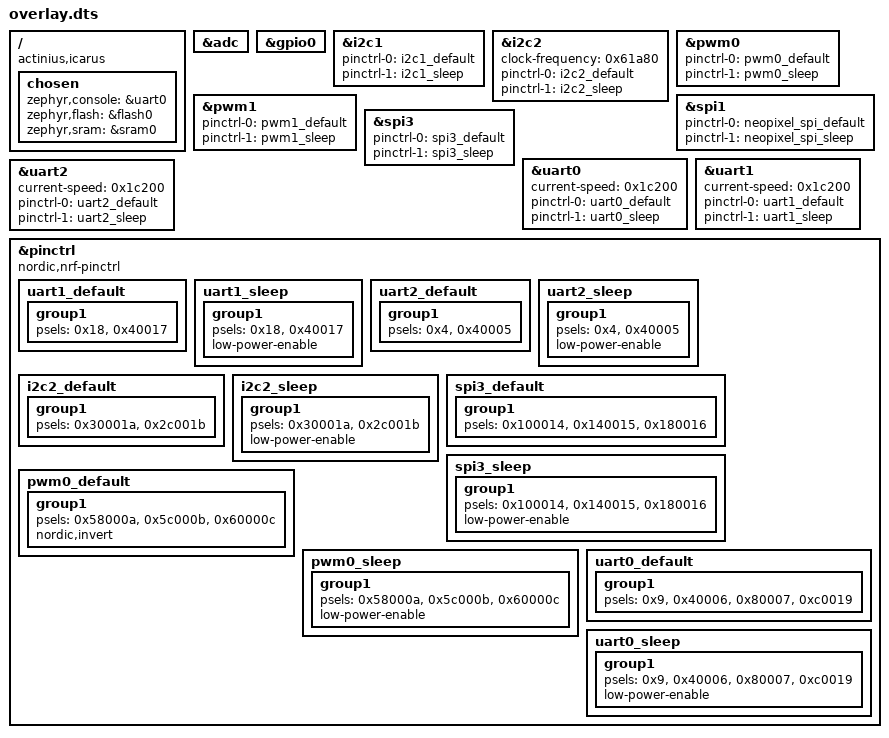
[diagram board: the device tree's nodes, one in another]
/ {
	compatible = "actinius,icarus";
	chosen {
		zephyr,console = &uart0;
		zephyr,flash = &flash0;
		zephyr,sram = &sram0;
	};
};
&adc{
	status = "okay";
};
&gpio0{
	status = "okay";
};
&i2c1{
	status = "okay";
	pinctrl-0 = < &i2c1_default >;
	pinctrl-1 = < &i2c1_sleep >;
	pinctrl-names = "default", "sleep";
};
&i2c2{
	clock-frequency = < 0x61a80 >;
	status = "okay";
	pinctrl-0 = < &i2c2_default >;
	pinctrl-1 = < &i2c2_sleep >;
	pinctrl-names = "default", "sleep";
};
&pwm0{
	status = "okay";
	pinctrl-0 = < &pwm0_default >;
	pinctrl-1 = < &pwm0_sleep >;
	pinctrl-names = "default", "sleep";
};
&pwm1{
	status = "okay";
	pinctrl-0 = < &pwm1_default >;
	pinctrl-1 = < &pwm1_sleep >;
	pinctrl-names = "default", "sleep";
};
&spi1{
	status = "okay";
	pinctrl-0 = < &neopixel_spi_default >;
	pinctrl-1 = < &neopixel_spi_sleep >;
	pinctrl-names = "default", "sleep";
};
&spi3{
	status = "okay";
	pinctrl-0 = < &spi3_default >;
	pinctrl-1 = < &spi3_sleep >;
	pinctrl-names = "default", "sleep";
};
&uart0{
	status = "okay";
	current-speed = < 0x1c200 >;
	pinctrl-0 = < &uart0_default >;
	pinctrl-1 = < &uart0_sleep >;
	pinctrl-names = "default", "sleep";
};
&uart1{
	status = "okay";
	current-speed = < 0x1c200 >;
	pinctrl-0 = < &uart1_default >;
	pinctrl-1 = < &uart1_sleep >;
	pinctrl-names = "default", "sleep";
};
&uart2{
	current-speed = < 0x1c200 >;
	pinctrl-0 = < &uart2_default >;
	pinctrl-1 = < &uart2_sleep >;
	pinctrl-names = "default", "sleep";
};
&pinctrl{
	compatible = "nordic,nrf-pinctrl";
	uart1_default: uart1_default {
		group1 {
			psels = < 0x18 >, < 0x40017 >;
		};
	};
	uart1_sleep: uart1_sleep {
		group1 {
			psels = < 0x18 >, < 0x40017 >;
			low-power-enable;
		};
	};
	uart2_default: uart2_default {
		group1 {
			psels = < 0x4 >, < 0x40005 >;
		};
	};
	uart2_sleep: uart2_sleep {
		group1 {
			psels = < 0x4 >, < 0x40005 >;
			low-power-enable;
		};
	};
	i2c2_default: i2c2_default {
		group1 {
			psels = < 0x30001a >, < 0x2c001b >;
		};
	};
	i2c2_sleep: i2c2_sleep {
		group1 {
			psels = < 0x30001a >, < 0x2c001b >;
			low-power-enable;
		};
	};
	spi3_default: spi3_default {
		group1 {
			psels = < 0x100014 >, < 0x140015 >, < 0x180016 >;
		};
	};
	spi3_sleep: spi3_sleep {
		group1 {
			psels = < 0x100014 >, < 0x140015 >, < 0x180016 >;
			low-power-enable;
		};
	};
	pwm0_default: pwm0_default {
		group1 {
			psels = < 0x58000a >, < 0x5c000b >, < 0x60000c >;
			nordic,invert;
		};
	};
	pwm0_sleep: pwm0_sleep {
		group1 {
			psels = < 0x58000a >, < 0x5c000b >, < 0x60000c >;
			low-power-enable;
		};
	};
	uart0_default: uart0_default {
		group1 {
			psels = < 0x9 >, < 0x40006 >, < 0x80007 >, < 0xc0019 >;
		};
	};
	uart0_sleep: uart0_sleep {
		group1 {
			psels = < 0x9 >, < 0x40006 >, < 0x80007 >, < 0xc0019 >;
			low-power-enable;
		};
	};
};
